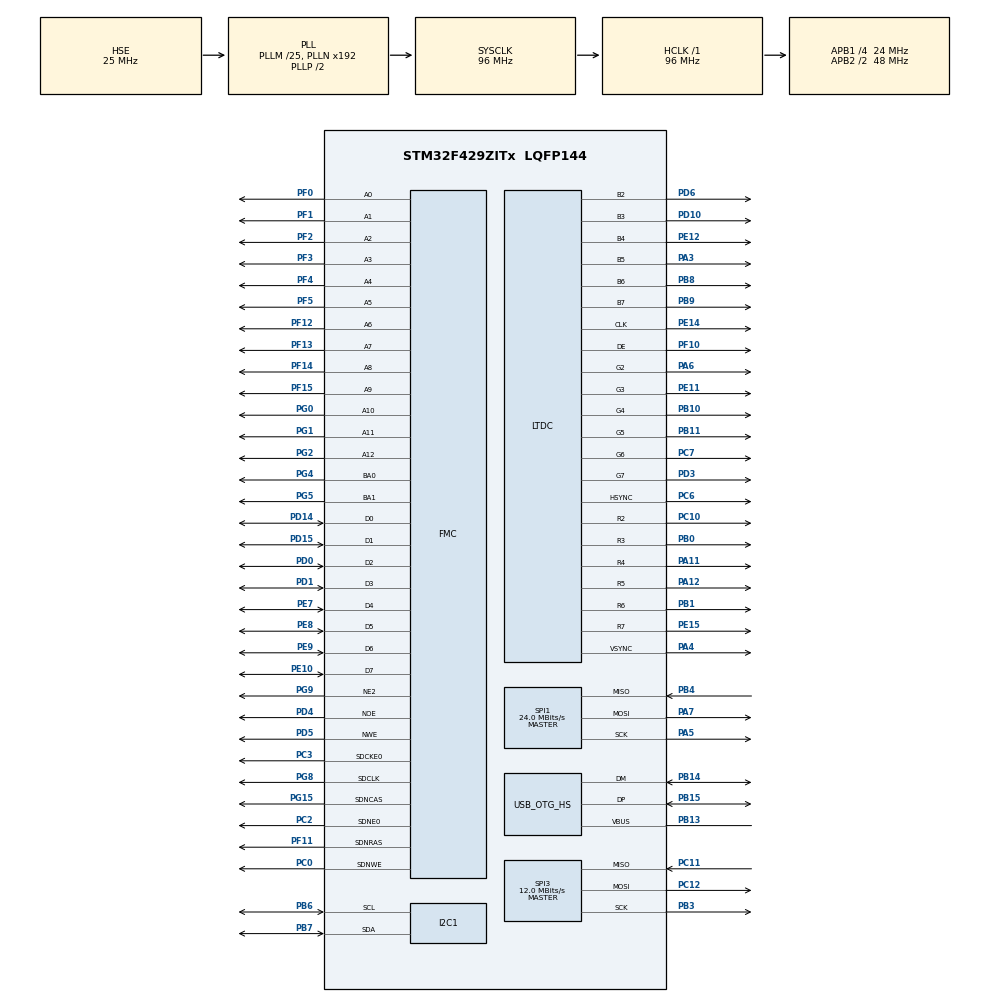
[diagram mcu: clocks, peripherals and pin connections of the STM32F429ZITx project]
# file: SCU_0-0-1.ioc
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FREERTOS.Tasks01=defaultTask,0,128,StartDefaultTask,Default,NULL
I2C1.I2C_Mode=I2C_Fast
Mcu.Family=STM32F4
Mcu.Name=STM32F429ZITx
Mcu.Package=LQFP144
NVIC.OTG_HS_IRQn=true\:5\:0\:false\:false\:true\:true\:false
NVIC.PriorityGroup=NVIC_PRIORITYGROUP_4
NVIC.TIM1_UP_TIM10_IRQn=true\:0\:0\:false\:false\:true\:false\:false
NVIC.TimeBase=TIM1_UP_TIM10_IRQn
NVIC.TimeBaseIP=TIM1
PA11.Mode=RGB666
PA11.Signal=LTDC_R4
PA12.Mode=RGB666
PA12.Signal=LTDC_R5
PA13.Mode=Serial_Wire
PA13.Signal=SYS_JTMS-SWDIO
PA14.Mode=Serial_Wire
PA14.Signal=SYS_JTCK-SWCLK
PA3.Mode=RGB666
PA3.Signal=LTDC_B5
PA4.Mode=RGB666
PA4.Signal=LTDC_VSYNC
PA5.Mode=Full_Duplex_Master
PA5.Signal=SPI1_SCK
PA6.Mode=RGB666
PA6.Signal=LTDC_G2
PA7.Mode=Full_Duplex_Master
PA7.Signal=SPI1_MOSI
PB0.Mode=RGB666
PB0.Signal=LTDC_R3
PB1.Mode=RGB666
PB1.Signal=LTDC_R6
PB10.Mode=RGB666
PB10.Signal=LTDC_G4
PB11.Mode=RGB666
PB11.Signal=LTDC_G5
PB13.Mode=Activate_VBUS_FS
PB13.Signal=USB_OTG_HS_VBUS
PB14.Mode=Device_Only_FS
PB14.Signal=USB_OTG_HS_DM
PB15.Mode=Device_Only_FS
PB15.Signal=USB_OTG_HS_DP
PB3.Mode=Full_Duplex_Master
PB3.Signal=SPI3_SCK
PB4.Mode=Full_Duplex_Master
PB4.Signal=SPI1_MISO
PB6.Mode=I2C
PB6.Signal=I2C1_SCL
PB7.Mode=I2C
PB7.Signal=I2C1_SDA
PB8.Mode=RGB666
PB8.Signal=LTDC_B6
PB9.Mode=RGB666
PB9.Signal=LTDC_B7
PC0.Signal=FMC_SDNWE
PC10.Mode=RGB666
PC10.Signal=LTDC_R2
PC11.Mode=Full_Duplex_Master
PC11.Signal=SPI3_MISO
PC12.Mode=Full_Duplex_Master
PC12.Signal=SPI3_MOSI
PC14/OSC32_IN.Mode=LSE-External-Oscillator
PC14/OSC32_IN.Signal=RCC_OSC32_IN
PC15/OSC32_OUT.Mode=LSE-External-Oscillator
PC15/OSC32_OUT.Signal=RCC_OSC32_OUT
PC2.Mode=SdramChipSelect1_1
PC2.Signal=FMC_SDNE0
PC3.Mode=SdramChipSelect1_1
PC3.Signal=FMC_SDCKE0
PC6.Mode=RGB666
PC6.Signal=LTDC_HSYNC
PC7.Mode=RGB666
PC7.Signal=LTDC_G6
PD0.Signal=FMC_D2_DA2
PD1.Signal=FMC_D3_DA3
PD10.Mode=RGB666
PD10.Signal=LTDC_B3
PD14.Signal=FMC_D0_DA0
PD15.Signal=FMC_D1_DA1
PD3.Mode=RGB666
PD3.Signal=LTDC_G7
PD4.Signal=FMC_NOE
PD5.Signal=FMC_NWE
PD6.Mode=RGB666
PD6.Signal=LTDC_B2
PE10.Signal=FMC_D7_DA7
PE11.Mode=RGB666
PE11.Signal=LTDC_G3
PE12.Mode=RGB666
PE12.Signal=LTDC_B4
PE14.Mode=RGB666
PE14.Signal=LTDC_CLK
PE15.Mode=RGB666
PE15.Signal=LTDC_R7
PE7.Signal=FMC_D4_DA4
PE8.Signal=FMC_D5_DA5
PE9.Signal=FMC_D6_DA6
PF0.Signal=FMC_A0
PF1.Signal=FMC_A1
PF10.Mode=RGB666
PF10.Signal=LTDC_DE
PF11.Signal=FMC_SDNRAS
PF12.Signal=FMC_A6
PF13.Signal=FMC_A7
PF14.Signal=FMC_A8
PF15.Signal=FMC_A9
PF2.Signal=FMC_A2
PF3.Signal=FMC_A3
PF4.Signal=FMC_A4
PF5.Signal=FMC_A5
PG0.Signal=FMC_A10
PG1.Signal=FMC_A11
PG15.Signal=FMC_SDNCAS
PG2.Signal=FMC_A12
PG4.Signal=FMC_A14_BA0
PG5.Signal=FMC_A15_BA1
PG8.Signal=FMC_SDCLK
PG9.Mode=NorPsramChipSelect2_3
PG9.Signal=FMC_NE2
PH0/OSC_IN.Mode=HSE-External-Oscillator
PH0/OSC_IN.Signal=RCC_OSC_IN
PH1/OSC_OUT.Mode=HSE-External-Oscillator
PH1/OSC_OUT.Signal=RCC_OSC_OUT
ProjectManager.HeapSize=0x200
ProjectManager.StackSize=0x400
ProjectManager.TargetToolchain=TrueSTUDIO
RCC.48MHZClocksFreq_Value=48000000
RCC.AHBFreq_Value=96000000
RCC.APB1CLKDivider=RCC_HCLK_DIV4
RCC.APB1Freq_Value=24000000
RCC.APB1TimFreq_Value=48000000
RCC.APB2CLKDivider=RCC_HCLK_DIV2
RCC.APB2Freq_Value=48000000
RCC.APB2TimFreq_Value=96000000
RCC.CortexFreq_Value=96000000
RCC.HCLKFreq_Value=96000000
RCC.HSE_VALUE=25000000
RCC.HSI_VALUE=16000000
RCC.PLLM=25
RCC.PLLSAIN=100
RCC.RCC_RTC_Clock_Source=RCC_RTCCLKSOURCE_LSI
RCC.SYSCLKFreq_VALUE=96000000
RCC.SYSCLKSource=RCC_SYSCLKSOURCE_PLLCLK
RCC.VCOOutputFreq_Value=192000000
SH.FMC_A0.0=FMC_A0,13b-sda1
SH.FMC_A0.1=FMC_A0,8b-a3
SH.FMC_A1.0=FMC_A1,13b-sda1
SH.FMC_A1.1=FMC_A1,8b-a3
SH.FMC_A10.0=FMC_A10,13b-sda1
SH.FMC_A11.0=FMC_A11,13b-sda1
SH.FMC_A12.0=FMC_A12,13b-sda1
SH.FMC_A14_BA0.0=FMC_BA0,FourSdramBanks1
SH.FMC_A15_BA1.0=FMC_BA1,FourSdramBanks1
SH.FMC_A2.0=FMC_A2,13b-sda1
SH.FMC_A2.1=FMC_A2,8b-a3
SH.FMC_A3.0=FMC_A3,13b-sda1
SH.FMC_A3.1=FMC_A3,8b-a3
SH.FMC_A4.0=FMC_A4,13b-sda1
SH.FMC_A4.1=FMC_A4,8b-a3
SH.FMC_A5.0=FMC_A5,13b-sda1
SH.FMC_A5.1=FMC_A5,8b-a3
SH.FMC_A6.0=FMC_A6,13b-sda1
SH.FMC_A6.1=FMC_A6,8b-a3
SH.FMC_A7.0=FMC_A7,13b-sda1
SH.FMC_A7.1=FMC_A7,8b-a3
SH.FMC_A8.0=FMC_A8,13b-sda1
SH.FMC_A9.0=FMC_A9,13b-sda1
SH.FMC_D0_DA0.0=FMC_D0,sd-8b-d1
SH.FMC_D0_DA0.1=FMC_D0,8b-d3
SH.FMC_D1_DA1.0=FMC_D1,sd-8b-d1
SH.FMC_D1_DA1.1=FMC_D1,8b-d3
SH.FMC_D2_DA2.0=FMC_D2,sd-8b-d1
SH.FMC_D2_DA2.1=FMC_D2,8b-d3
SH.FMC_D3_DA3.0=FMC_D3,sd-8b-d1
SH.FMC_D3_DA3.1=FMC_D3,8b-d3
SH.FMC_D4_DA4.0=FMC_D4,sd-8b-d1
SH.FMC_D4_DA4.1=FMC_D4,8b-d3
SH.FMC_D5_DA5.0=FMC_D5,sd-8b-d1
SH.FMC_D5_DA5.1=FMC_D5,8b-d3
SH.FMC_D6_DA6.0=FMC_D6,sd-8b-d1
SH.FMC_D6_DA6.1=FMC_D6,8b-d3
SH.FMC_D7_DA7.0=FMC_D7,sd-8b-d1
SH.FMC_D7_DA7.1=FMC_D7,8b-d3
SH.FMC_NOE.0=FMC_NOE,NorFlash3
SH.FMC_NWE.0=FMC_NWE,NorFlash3
SH.FMC_SDCLK.0=FMC_SDCLK,13b-sda1
SH.FMC_SDNCAS.0=FMC_SDNCAS,13b-sda1
SH.FMC_SDNRAS.0=FMC_SDNRAS,13b-sda1
SH.FMC_SDNWE.0=FMC_SDNWE,13b-sda1
SPI1.CalculateBaudRate=24.0 MBits/s
SPI1.Direction=SPI_DIRECTION_2LINES
SPI1.Mode=SPI_MODE_MASTER
SPI1.VirtualType=VM_MASTER
SPI3.CalculateBaudRate=12.0 MBits/s
SPI3.Direction=SPI_DIRECTION_2LINES
SPI3.Mode=SPI_MODE_MASTER
SPI3.VirtualType=VM_MASTER
USB_DEVICE.CLASS_NAME_HS=CUSTOMHID
USB_DEVICE.VirtualMode-CUSTOM_HID_HS=CustomHid
USB_DEVICE.VirtualModeHS=Custom_Hid_HS
USB_OTG_HS.VirtualMode-Device_Only_FS=Device_Only_FS
VP_DMA2D_VS_DMA2D.Mode=DMA2D_Activate
VP_FREERTOS_VS_ENABLE.Mode=Enabled
VP_SYS_VS_tim1.Mode=TIM1
VP_TIM6_VS_ClockSourceINT.Mode=Enable_Timer
VP_TIM7_VS_ClockSourceINT.Mode=Enable_Timer
VP_USB_DEVICE_VS_USB_DEVICE_CUSTOM_HID_HS.Mode=CUSTOM_HID_HS
board=custom

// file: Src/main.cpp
/* USER CODE BEGIN Header */
/**
  ******************************************************************************
  * @file           : main.c
  * @brief          : Main program body
  ******************************************************************************
  * This notice applies to any and all portions of this file
  * that are not between comment pairs USER CODE BEGIN and
  * USER CODE END. Other portions of this file, whether
  * inserted by the user or by software development tools
  * are owned by their respective copyright owners.
  *
  * Copyright (c) 2018 STMicroelectronics International N.V.
  * All rights reserved.
  *
  * Redistribution and use in source and binary forms, with or without
  * modification, are permitted, provided that the following conditions are met:
  *
  * 1. Redistribution of source code must retain the above copyright notice,
  *    this list of conditions and the following disclaimer.
  * 2. Redistributions in binary form must reproduce the above copyright notice,
  *    this list of conditions and the following disclaimer in the documentation
  *    and/or other materials provided with the distribution.
  * 3. Neither the name of STMicroelectronics nor the names of other
  *    contributors to this software may be used to endorse or promote products
  *    derived from this software without specific written permission.
  * 4. This software, including modifications and/or derivative works of this
  *    software, must execute solely and exclusively on microcontroller or
  *    microprocessor devices manufactured by or for STMicroelectronics.
  * 5. Redistribution and use of this software other than as permitted under
  *    this license is void and will automatically terminate your rights under
  *    this license.
  *
  * THIS SOFTWARE IS PROVIDED BY STMICROELECTRONICS AND CONTRIBUTORS "AS IS"
  * AND ANY EXPRESS, IMPLIED OR STATUTORY WARRANTIES, INCLUDING, BUT NOT
  * LIMITED TO, THE IMPLIED WARRANTIES OF MERCHANTABILITY, FITNESS FOR A
  * PARTICULAR PURPOSE AND NON-INFRINGEMENT OF THIRD PARTY INTELLECTUAL PROPERTY
  * RIGHTS ARE DISCLAIMED TO THE FULLEST EXTENT PERMITTED BY LAW. IN NO EVENT
  * SHALL STMICROELECTRONICS OR CONTRIBUTORS BE LIABLE FOR ANY DIRECT, INDIRECT,
  * INCIDENTAL, SPECIAL, EXEMPLARY, OR CONSEQUENTIAL DAMAGES (INCLUDING, BUT NOT
  * LIMITED TO, PROCUREMENT OF SUBSTITUTE GOODS OR SERVICES; LOSS OF USE, DATA,
  * OR PROFITS; OR BUSINESS INTERRUPTION) HOWEVER CAUSED AND ON ANY THEORY OF
  * LIABILITY, WHETHER IN CONTRACT, STRICT LIABILITY, OR TORT (INCLUDING
  * NEGLIGENCE OR OTHERWISE) ARISING IN ANY WAY OUT OF THE USE OF THIS SOFTWARE,
  * EVEN IF ADVISED OF THE POSSIBILITY OF SUCH DAMAGE.
  *
  ******************************************************************************
  */
/* USER CODE END Header */

#ifdef __cplusplus
 extern "C" {
#endif

#include "main.h"
#include "cmsis_os.h"
#include "dma2d.h"
#include "i2c.h"
#include "ltdc.h"
#include "spi.h"
#include "tim.h"
#include "usb_device.h"
#include "gpio.h"
#include "fmc.h"

/* USER CODE BEGIN Includes */
#include "../Drivers/Expanders/MCP/MCP23008/MCP23008.h"
#include "../Drivers/Expanders/MCP/MCP23017/MCP23017.h"
#include "../Drivers/LEDDrivers/NXP/PCA9622/PCA9622.h"
#include "../Drivers/LEDDrivers/NXP/PCA9624/PCA9624.h"
#include "../Drivers/LEDDrivers/NXP/PCA9626/PCA9626.h"
/* USER CODE END Includes */

/* USER CODE BEGIN PV */
#ifdef SCU8D_001
 PCA9626 SCU_LED_DRIVER;
#endif
/* USER CODE END PV */

void SystemClock_Config(void);
void MX_FREERTOS_Init(void);

int main(void)
{

  /* MCU Configuration--------------------------------------------------------*/

  /* Reset of all peripherals, Initializes the Flash interface and the Systick. */
  HAL_Init();

  /* Configure the system clock */
  SystemClock_Config();

  /* Initialize all configured peripherals */
  MX_GPIO_Init();
  MX_LTDC_Init();
  MX_DMA2D_Init();
  MX_I2C1_Init();
  MX_TIM7_Init();
  MX_TIM6_Init();
  MX_SPI3_Init();
  MX_SPI1_Init();
  MX_FMC_Init();
  /* USER CODE BEGIN 2 */

  SCU_LED_DRIVER.init(1, LEDDRIVERADD);
  SCU_LED_DRIVER.begin();

  /* USER CODE END 2 */

  /* Call init function for freertos objects (in freertos.c) */
  MX_FREERTOS_Init();

  /* Start scheduler */
  osKernelStart();

  /* We should never get here as control is now taken by the scheduler */

  /* Infinite loop */

  while (1)
  {

	  //Check Input on any of the interrupt GPIO Inputs
	  //If so, Trigger read i2c
	  //If internal data, process perform needed operation (button input that controls a screen behavior)
	  //Else, send serial information to the PC on any inputs that have changed status

  }
}

void SystemClock_Config(void)
{
  RCC_OscInitTypeDef RCC_OscInitStruct = {0};
  RCC_ClkInitTypeDef RCC_ClkInitStruct = {0};
  RCC_PeriphCLKInitTypeDef PeriphClkInitStruct = {0};

  /**Configure the main internal regulator output voltage
  */
  __HAL_RCC_PWR_CLK_ENABLE();
  __HAL_PWR_VOLTAGESCALING_CONFIG(PWR_REGULATOR_VOLTAGE_SCALE3);
  /**Initializes the CPU, AHB and APB busses clocks
  */
  RCC_OscInitStruct.OscillatorType = RCC_OSCILLATORTYPE_HSE;
  RCC_OscInitStruct.HSEState = RCC_HSE_ON;
  RCC_OscInitStruct.PLL.PLLState = RCC_PLL_ON;
  RCC_OscInitStruct.PLL.PLLSource = RCC_PLLSOURCE_HSE;
  RCC_OscInitStruct.PLL.PLLM = 25;
  RCC_OscInitStruct.PLL.PLLN = 192;
  RCC_OscInitStruct.PLL.PLLP = RCC_PLLP_DIV2;
  RCC_OscInitStruct.PLL.PLLQ = 4;
  if (HAL_RCC_OscConfig(&RCC_OscInitStruct) != HAL_OK)
  {
    Error_Handler();
  }
  /**Initializes the CPU, AHB and APB busses clocks
  */
  RCC_ClkInitStruct.ClockType = RCC_CLOCKTYPE_HCLK|RCC_CLOCKTYPE_SYSCLK
                              |RCC_CLOCKTYPE_PCLK1|RCC_CLOCKTYPE_PCLK2;
  RCC_ClkInitStruct.SYSCLKSource = RCC_SYSCLKSOURCE_PLLCLK;
  RCC_ClkInitStruct.AHBCLKDivider = RCC_SYSCLK_DIV1;
  RCC_ClkInitStruct.APB1CLKDivider = RCC_HCLK_DIV4;
  RCC_ClkInitStruct.APB2CLKDivider = RCC_HCLK_DIV2;

  if (HAL_RCC_ClockConfig(&RCC_ClkInitStruct, FLASH_LATENCY_3) != HAL_OK)
  {
    Error_Handler();
  }
  PeriphClkInitStruct.PeriphClockSelection = RCC_PERIPHCLK_LTDC;
  PeriphClkInitStruct.PLLSAI.PLLSAIN = 100;
  PeriphClkInitStruct.PLLSAI.PLLSAIR = 2;
  PeriphClkInitStruct.PLLSAIDivR = RCC_PLLSAIDIVR_2;
  if (HAL_RCCEx_PeriphCLKConfig(&PeriphClkInitStruct) != HAL_OK)
  {
    Error_Handler();
  }
}

void HAL_TIM_PeriodElapsedCallback(TIM_HandleTypeDef *htim)
{
  if (htim->Instance == TIM1) {
    HAL_IncTick();
  }
}

void Error_Handler(void)
{
}

#ifdef __cplusplus
}
#endif
/************************ (C) COPYRIGHT STMicroelectronics *****END OF FILE****/
